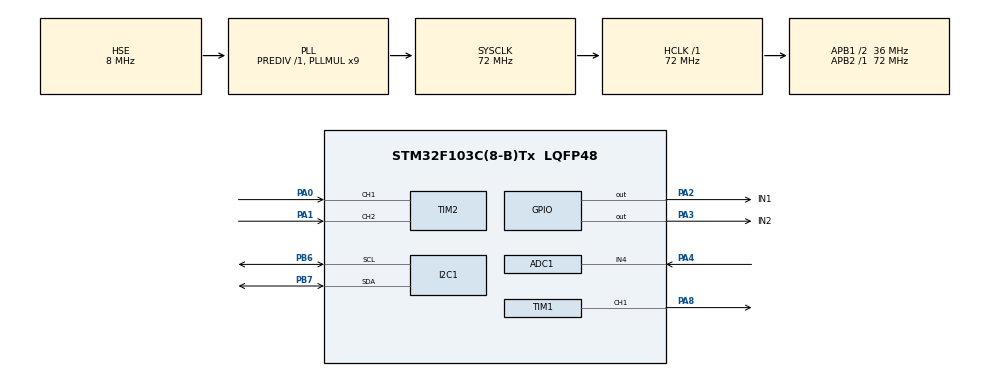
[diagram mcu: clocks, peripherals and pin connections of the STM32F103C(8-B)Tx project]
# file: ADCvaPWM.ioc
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ADC1.Channel-1\#ChannelRegularConversion=ADC_CHANNEL_4
ADC1.ContinuousConvMode=ENABLE
ADC1.NbrOfConversionFlag=1
ADC1.Rank-1\#ChannelRegularConversion=1
ADC1.SamplingTime-1\#ChannelRegularConversion=ADC_SAMPLETIME_55CYCLES_5
ADC1.master=1
I2C1.NoStretchMode=I2C_NOSTRETCH_ENABLE
Mcu.Family=STM32F1
Mcu.Name=STM32F103C(8-B)Tx
Mcu.Package=LQFP48
NVIC.PriorityGroup=NVIC_PRIORITYGROUP_4
NVIC.TIM3_IRQn=true\:0\:0\:false\:false\:true\:true\:true\:true
PA0-WKUP.Signal=S_TIM2_CH1_ETR
PA1.Signal=S_TIM2_CH2
PA13.Mode=Serial_Wire
PA13.Signal=SYS_JTMS-SWDIO
PA14.Mode=Serial_Wire
PA14.Signal=SYS_JTCK-SWCLK
PA2.GPIO_Label=IN1
PA2.GPIO_Speed=GPIO_SPEED_FREQ_HIGH
PA2.Signal=GPIO_Output
PA3.GPIO_Label=IN2
PA3.GPIO_Speed=GPIO_SPEED_FREQ_HIGH
PA3.PinState=GPIO_PIN_RESET
PA3.Signal=GPIO_Output
PA4.Signal=ADCx_IN4
PA8.GPIO_Speed=GPIO_SPEED_FREQ_HIGH
PA8.Signal=S_TIM1_CH1
PB6.Mode=I2C
PB6.Signal=I2C1_SCL
PB7.Mode=I2C
PB7.Signal=I2C1_SDA
PD0-OSC_IN.Mode=HSE-External-Oscillator
PD0-OSC_IN.Signal=RCC_OSC_IN
PD1-OSC_OUT.Mode=HSE-External-Oscillator
PD1-OSC_OUT.Signal=RCC_OSC_OUT
ProjectManager.HeapSize=0x200
ProjectManager.StackSize=0x400
ProjectManager.TargetToolchain=MDK-ARM V5.32
RCC.ADCPresc=RCC_ADCPCLK2_DIV6
RCC.AHBFreq_Value=72000000
RCC.APB1CLKDivider=RCC_HCLK_DIV2
RCC.APB1Freq_Value=36000000
RCC.APB1TimFreq_Value=72000000
RCC.APB2Freq_Value=72000000
RCC.APB2TimFreq_Value=72000000
RCC.HCLKFreq_Value=72000000
RCC.PLLMUL=RCC_PLL_MUL9
RCC.PLLSourceVirtual=RCC_PLLSOURCE_HSE
RCC.SYSCLKFreq_VALUE=72000000
RCC.SYSCLKSource=RCC_SYSCLKSOURCE_PLLCLK
RCC.USBFreq_Value=72000000
SH.ADCx_IN4.0=ADC1_IN4,IN4
SH.S_TIM1_CH1.0=TIM1_CH1,PWM Generation1 CH1
SH.S_TIM2_CH1_ETR.0=TIM2_CH1,Encoder_Interface
SH.S_TIM2_CH2.0=TIM2_CH2,Encoder_Interface
TIM1.Channel-PWM\ Generation1\ CH1=TIM_CHANNEL_1
TIM1.OCPolarity_1=TIM_OCPOLARITY_LOW
TIM1.Period=999
TIM1.Prescaler=71
TIM2.EncoderMode=TIM_ENCODERMODE_TI12
TIM3.Period=499
TIM3.Prescaler=7199
VP_TIM3_VS_ClockSourceINT.Mode=Internal
board=custom

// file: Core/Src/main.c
/* USER CODE BEGIN Header */
/**
  ******************************************************************************
  * @file           : main.c
  * @brief          : Main program body
  ******************************************************************************
  * @attention
  *
  * Copyright (c) 2026 STMicroelectronics.
  * All rights reserved.
  *
  * This software is licensed under terms that can be found in the LICENSE file
  * in the root directory of this software component.
  * If no LICENSE file comes with this software, it is provided AS-IS.
  *
  ******************************************************************************
  */
/* USER CODE END Header */
#include "main.h"
#include "adc.h"
#include "i2c.h"
#include "tim.h"
#include "gpio.h"

/* USER CODE BEGIN PV */
I2C_LCD_HandleTypeDef my_lcd;
/* USER CODE END PV */

void SystemClock_Config(void);

int main(void)
{

  /* MCU Configuration--------------------------------------------------------*/

  /* Reset of all peripherals, Initializes the Flash interface and the Systick. */
  HAL_Init();

  /* Configure the system clock */
  SystemClock_Config();

  /* Initialize all configured peripherals */
  MX_GPIO_Init();
  MX_ADC1_Init();
  MX_TIM1_Init();
  MX_TIM2_Init();
  MX_TIM3_Init();
  MX_I2C1_Init();
  /* USER CODE BEGIN 2 */
HAL_TIM_PWM_Start(&htim1, TIM_CHANNEL_1);       // B?t PWM ch�n PA8
HAL_ADC_Start(&hadc1);                           // B?t ADC ch�n PA4
HAL_TIM_Encoder_Start(&htim2, TIM_CHANNEL_ALL); // B?t d?m xung Encoder PA0, PA1

// Thi?t l?p chi?u quay c? d?nh (IN1=1, IN2=0)
HAL_GPIO_WritePin(GPIOA, GPIO_PIN_2, GPIO_PIN_SET);
HAL_GPIO_WritePin(GPIOA, GPIO_PIN_3, GPIO_PIN_RESET);
  /* USER CODE END 2 */

  /* Infinite loop */
  while (1)
  {

  }
}

void SystemClock_Config(void)
{
  RCC_OscInitTypeDef RCC_OscInitStruct = {0};
  RCC_ClkInitTypeDef RCC_ClkInitStruct = {0};
  RCC_PeriphCLKInitTypeDef PeriphClkInit = {0};

  /** Initializes the RCC Oscillators according to the specified parameters
  * in the RCC_OscInitTypeDef structure.
  */
  RCC_OscInitStruct.OscillatorType = RCC_OSCILLATORTYPE_HSE;
  RCC_OscInitStruct.HSEState = RCC_HSE_ON;
  RCC_OscInitStruct.HSEPredivValue = RCC_HSE_PREDIV_DIV1;
  RCC_OscInitStruct.HSIState = RCC_HSI_ON;
  RCC_OscInitStruct.PLL.PLLState = RCC_PLL_ON;
  RCC_OscInitStruct.PLL.PLLSource = RCC_PLLSOURCE_HSE;
  RCC_OscInitStruct.PLL.PLLMUL = RCC_PLL_MUL9;
  if (HAL_RCC_OscConfig(&RCC_OscInitStruct) != HAL_OK)
  {
    Error_Handler();
  }

  /** Initializes the CPU, AHB and APB buses clocks
  */
  RCC_ClkInitStruct.ClockType = RCC_CLOCKTYPE_HCLK|RCC_CLOCKTYPE_SYSCLK
                              |RCC_CLOCKTYPE_PCLK1|RCC_CLOCKTYPE_PCLK2;
  RCC_ClkInitStruct.SYSCLKSource = RCC_SYSCLKSOURCE_PLLCLK;
  RCC_ClkInitStruct.AHBCLKDivider = RCC_SYSCLK_DIV1;
  RCC_ClkInitStruct.APB1CLKDivider = RCC_HCLK_DIV2;
  RCC_ClkInitStruct.APB2CLKDivider = RCC_HCLK_DIV1;

  if (HAL_RCC_ClockConfig(&RCC_ClkInitStruct, FLASH_LATENCY_2) != HAL_OK)
  {
    Error_Handler();
  }
  PeriphClkInit.PeriphClockSelection = RCC_PERIPHCLK_ADC;
  PeriphClkInit.AdcClockSelection = RCC_ADCPCLK2_DIV6;
  if (HAL_RCCEx_PeriphCLKConfig(&PeriphClkInit) != HAL_OK)
  {
    Error_Handler();
  }
}

void Error_Handler(void)
{
  __disable_irq();
  while (1)
  {
  }
}
